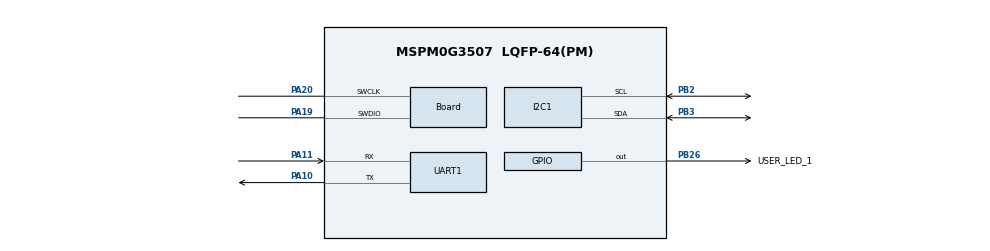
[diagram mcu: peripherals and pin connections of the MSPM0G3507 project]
/**
 * These arguments were used when this file was generated. They will be automatically applied on subsequent loads
 * via the GUI or CLI. Run CLI with '--help' for additional information on how to override these arguments.
 */
//@cliArgs --device "MSPM0G350X" --package "LQFP-64(PM)" --part "Default"
//@v2CliArgs --device "MSPM0G3507" --package "LQFP-64(PM)"
// @cliArgs --board /ti/boards/LP_MSPM0G3507 --rtos nortos

/**
 * Import the modules used in this configuration.
 */
const GPIO   = scripting.addModule("/ti/driverlib/GPIO", {}, false);
const GPIO1  = GPIO.addInstance();
const I2C    = scripting.addModule("/ti/driverlib/I2C", {}, false);
const I2C1   = I2C.addInstance();
const SYSCTL = scripting.addModule("/ti/driverlib/SYSCTL");
const UART   = scripting.addModule("/ti/driverlib/UART", {}, false);
const UART1  = UART.addInstance();

/**
 * Write custom configuration values to the imported modules.
 */
GPIO1.$name                         = "GPIO_LEDS";
GPIO1.associatedPins[0].$name       = "USER_LED_1";
GPIO1.associatedPins[0].assignedPin = "26";
GPIO1.associatedPins[0].pin.$assign = "PB26";

const Board                       = scripting.addModule("/ti/driverlib/Board", {}, false);
Board.peripheral.$assign          = "DEBUGSS";
Board.peripheral.swclkPin.$assign = "PA20";
Board.peripheral.swdioPin.$assign = "PA19";

I2C1.$name                     = "I2C";
I2C1.basicEnableController     = true;
I2C1.basicControllerBusSpeed   = 100000;
I2C1.advAnalogGlitchFilter     = "DISABLED";
I2C1.peripheral.$assign        = "I2C1";
I2C1.peripheral.sdaPin.$assign = "PB3";
I2C1.peripheral.sclPin.$assign = "PB2";

UART1.$name                    = "UART_0";
UART1.enableFIFO               = true;
UART1.enableDMARX              = false;
UART1.enableDMATX              = false;
UART1.targetBaudRate           = 115200;
UART1.enableInternalLoopback   = false;
UART1.rxFifoThreshold          = "DL_UART_RX_FIFO_LEVEL_1_2_FULL";
UART1.peripheral.$assign       = "UART0";
UART1.peripheral.rxPin.$assign = "PA11";
UART1.peripheral.txPin.$assign = "PA10";

SYSCTL.forceDefaultClkConfig = true;
SYSCTL.clockTreeEn           = true;
